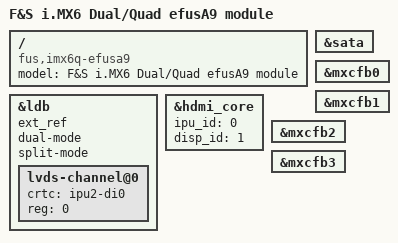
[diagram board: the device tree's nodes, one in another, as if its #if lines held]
/*
 * Copyright (C) 2016 F&S Elektronik Systeme GmbH
 *
 * This program is free software; you can redistribute it and/or modify
 * it under the terms of the GNU General Public License version 2 as
 * published by the Free Software Foundation.
 */

/dts-v1/;

/* Set board revision as 3-digit number, e.g. 110 for board rev. 1.10 */
#define CONFIG_EFUSA9_BOARD_REVISION	120

/* CONFIGURE 5V LVDS POWER SUPPLY */
#if (CONFIG_EFUSA9_BOARD_REVISION >= 121)
/* With REV121 you can connect LVDS displays that need 5V.
   Most displays run with 3.3V. Define the variable below to configure the
   gpio used for switching to 5V. */
//#define CONFIG_EFUSA9_5V_LVDS
#endif


/* ENABLE DISPLAYS */
/* The following display config will be converted to Kconfig in the future */
/* Keep the order, e.G. activating D0 and D3 but not D2 is not allowed */
/* Define this if you have at least one display (D0) */
#define CONFIG_EFUSA9_D0
/* Define this if you have a second display (D1) */
#define CONFIG_EFUSA9_D1
/* Define this if you have a third display (D2) */
//#define CONFIG_EFUSA9_D2
/* Define this if you have a fourth display (D3) */
//#define CONFIG_EFUSA9_D3

/* CONFIGURE DISPLAY 0 */
#ifdef CONFIG_EFUSA9_D0
/* Activate exactly one entry for the type of display D0 */
#define CONFIG_EFUSA9_D0_LCD				// LCD
//#define CONFIG_EFUSA9_D0_LVDS				// LVDS
//#define CONFIG_EFUSA9_D0_HDMI				// HDMI
/*
 * Define a mode_str entry for display D0 (depends on display type above)
 * See the following files for possible values:
 *   LVDS: drivers/video/mxc/ldb.c
 *   LCD:  drivers/video/mxc/mxc_lcdif.c
 *   HDMI: drivers/video/fbdev/mxc/mxc_hdmi.c (actually fetched from panel via EDID)
 */
#ifdef CONFIG_EFUSA9_D0_LCD
	#define CONFIG_EFUSA9_D0_MODE_STR "LCD-ET070080"	// LCD
#elif defined(CONFIG_EFUSA9_D0_LVDS)
	#define CONFIG_EFUSA9_D0_MODE_STR "LDB-WVGA"		// LVDS
#elif defined(CONFIG_EFUSA9_D0_HDMI)
	#define CONFIG_EFUSA9_D0_MODE_STR "1920x1080M@60"	// HDMI
#endif
#endif // CONFIG_EFUSA9_D0

/* CONFIGURE DISPLAY 1 */
#ifdef CONFIG_EFUSA9_D1
/* Activate exactly one entry for the type of display D1 */
//#define CONFIG_EFUSA9_D1_LCD				// LCD
#define CONFIG_EFUSA9_D1_LVDS				// LVDS
//#define CONFIG_EFUSA9_D1_HDMI				// HDMI
/* Define a mode_str entry for display D1 (see comment for D0 above) */
#ifdef CONFIG_EFUSA9_D1_LVDS
	#define CONFIG_EFUSA9_D1_MODE_STR "LDB-WVGA"		// LVDS
#elif defined(CONFIG_EFUSA9_D1_HDMI)
	#define CONFIG_EFUSA9_D1_MODE_STR "1920x1080M@60"	// HDMI
#elif	defined(CONFIG_EFUSA9_D1_LCD)
	#define CONFIG_EFUSA9_D1_MODE_STR "LCD-ET070080"	// LCD
#endif
#endif // CONFIG_EFUSA9_D1

/* CONFIGURE DISPLAY 2 */
#ifdef CONFIG_EFUSA9_D2
/* Activate exactly one entry for the type of display D2 */
//#define CONFIG_EFUSA9_D2_LCD				// LCD
//#define CONFIG_EFUSA9_D2_LVDS				// LVDS
#define CONFIG_EFUSA9_D2_HDMI				// HDMI
/* Define a mode_str entry for display D2 (see comment for D0 above) */
#ifdef CONFIG_EFUSA9_D2_LVDS
	#define CONFIG_EFUSA9_D2_MODE_STR "LDB-WVGA"		// LVDS
#elif defined(CONFIG_EFUSA9_D2_HDMI)
	#define CONFIG_EFUSA9_D2_MODE_STR "1920x1080M@60"	// HDMI
#elif	defined(CONFIG_EFUSA9_D2_LCD)
	#define CONFIG_EFUSA9_D2_MODE_STR "LCD-ET070080"	// LCD
#endif
#endif // CONFIG_EFUSA9_D2

/* CONFIGURE DISPLAY 3 */
#ifdef CONFIG_EFUSA9_D3
/* Activate exactly one entry for the type of display D3 */
//#define CONFIG_EFUSA9_D3_LCD				// LCD
#define CONFIG_EFUSA9_D3_LVDS				// LVDS
//#define CONFIG_EFUSA9_D3_HDMI				// HDMI
/* Define a mode_str entry for display D3 (see comment for D0 above) */
#ifdef CONFIG_EFUSA9_D3_LVDS
	#define CONFIG_EFUSA9_D3_MODE_STR "LDB-WVGA"		// LVDS
#elif defined(CONFIG_EFUSA9_D3_HDMI)
	#define CONFIG_EFUSA9_D3_MODE_STR "1920x1080M@60"	// HDMI
#elif	defined(CONFIG_EFUSA9_D3_LCD)
	#define CONFIG_EFUSA9_D3_MODE_STR "LCD-ET070080"	// LCD
#endif
#endif // CONFIG_EFUSA9_D3

/* CONFIGURE LVDS MULTIDISPLAY*/
/* Two LVDS displays act as two independent displays (with two fb) by default.
   Apart from this  can choose between dual-mode and split-mode */
#if defined(CONFIG_EFUSA9_D0_LVDS) && defined(CONFIG_EFUSA9_D1_LVDS)
/* one LVDS display per channel, one framebuffer for both */
//#define CONFIG_EFUSA9_LVDS_DUAL_MODE
/* two channels for 'split-mode-display', one framebuffer */
//#define CONFIG_EFUSA9_LVDS_SPLIT_MODE
#endif

/* Do some settings to make configurations easier */
#if defined(CONFIG_EFUSA9_D0_LCD) || defined(CONFIG_EFUSA9_D1_LCD) ||\
    defined(CONFIG_EFUSA9_D2_LCD) || defined(CONFIG_EFUSA9_D3_LCD)
#define CONFIG_EFUSA9_LCD // activates LCD node
#endif
#if defined(CONFIG_EFUSA9_D0_HDMI) || defined(CONFIG_EFUSA9_D1_HDMI) ||\
    defined(CONFIG_EFUSA9_D2_HDMI) || defined(CONFIG_EFUSA9_D3_HDMI)
#define CONFIG_EFUSA9_HDMI // activates HDMI node
#endif

#if defined(CONFIG_EFUSA9_D0_LVDS) || defined(CONFIG_EFUSA9_D1_LVDS) ||\
    defined(CONFIG_EFUSA9_D2_LVDS) || defined(CONFIG_EFUSA9_D3_LVDS)
#define CONFIG_EFUSA9_LVDS // activates LVDS node
#endif

/* HDMI */
#ifdef CONFIG_EFUSA9_HDMI
#define CONFIG_EFUSA9_HDMI_AUDIO
#define CONFIG_EFUSA9_HDMI_CEC
#endif


/*
 * Configure touch screen:
 *
 * - 4-wire/5-wire analog resistive touch, touch controller on SKIT
 * - 4-wire/5-wire analog resistive touch, touch controller on RGB LCD adapter
 * - PCAP touch based on Maxtouch controller (MXT224, etc), on Touch Connector
 * - PCAP touch based on Focaltech controller (FT5x06), on Touch Connector
 *
 * On efusA9, all touches use the same interrupt line and I2C bus, so do not
 * select more than one entry! Select none if you do not need touch support.
 */
//#define CONFIG_EFUSA9_4WTOUCH_SX8655_ONBOARD
#define CONFIG_EFUSA9_4WTOUCH_SX8655_RGBADAPTER
//#define CONFIG_EFUSA9_CAPTOUCH_MXT224
//#define CONFIG_EFUSA9_CAPTOUCH_FT5x06

/* CMA: Set 320 MB for Continuous Memory Allocator */
#define CONFIG_EFUSA9_CMA_SIZE		0x14000000

/* NAND */
#define CONFIG_EFUSA9_NAND

/* AUDIO */
#define CONFIG_EFUSA9_SGTL5000_AUDIO

/* Camera connected */
#define CONFIG_EFUSA9_CAMERA

/* Camera on parallel CSI interface */
//#define CONFIG_EFUSA9_PARALLEL_CAMERA

/* Camera on serial MIPI CSI interface */
#define CONFIG_EFUSA9_SERIAL_CAMERA

/* SD-CARD - SD_A is micro SD; SD_B is normalsize SD */
#define CONFIG_EFUSA9_SD_A
#define CONFIG_EFUSA9_SD_B

/* SATA */
#define CONFIG_EFUSA9_SATA

/* EMMC */
//#define CONFIG_EFUSA9_EMMC

/* I2C */
#define CONFIG_EFUSA9_I2C_A
#define CONFIG_EFUSA9_I2C_B
#define CONFIG_EFUSA9_I2C_C

/* SPI */
#define CONFIG_EFUSA9_SPI_A
#define CONFIG_EFUSA9_SPI_B

/* UART */
#define CONFIG_EFUSA9_UART_A
#define CONFIG_EFUSA9_UART_B
#define CONFIG_EFUSA9_UART_C
#define CONFIG_EFUSA9_UART_D


#include "imx6q.dtsi"
#include "efusa9qdl.dtsi"

/ {
	model = "F&S i.MX6 Dual/Quad efusA9 module";
	compatible = "fus,imx6q-efusa9", "fsl,imx6q";
};

/* i.MX6 Dual and Quad can have SATA */
#ifdef CONFIG_EFUSA9_SATA
&sata{
	status = "okay";
};

#endif
#ifdef CONFIG_EFUSA9_LVDS
&ldb {
	ext_ref;
#ifdef CONFIG_EFUSA9_LVDS_DUAL_MODE
	 dual-mode;
#endif
#ifdef CONFIG_EFUSA9_LVDS_SPLIT_MODE
	split-mode;
#endif

#ifdef CONFIG_EFUSA9_D2 		// 3 or 4 displays
#if defined(CONFIG_EFUSA9_LCD) && defined(CONFIG_EFUSA9_HDMI) &&\
    !defined(CONFIG_EFUSA9_D3) 	// 3 displays: LCD, HDMI and LVDS
	lvds-channel@0 {
		crtc = "ipu2-di0";
		reg = <0>;
		status = "okay";
	};
#else	// remaining combinations with 3 or 4 displays
	lvds-channel@0 {
		crtc = "ipu2-di0";
		reg = <0>;
		status = "okay";
	};
	lvds-channel@1 {
		crtc = "ipu2-di1";
		reg = <1>;
		status = "okay";
	};

#endif
#else // 1 or 2 displays

#ifdef CONFIG_EFUSA9_LCD		//if LCD is enabled too, LVDS uses di1
	lvds-channel@0 {
		crtc = "ipu1-di1"; 	//ipu1-di1 means ipu 0, di1
		reg = <0>;
		status = "okay";
	};
#else
	lvds-channel@0 {		//default LVDS uses di0
		crtc = "ipu1-di0";
		reg = <0>;
		status = "okay";
	};
#endif
#ifdef CONFIG_EFUSA9_D1_LVDS		//if both LVDS channels are used
	lvds-channel@1 {		//dual and split mode ignore this node
		crtc = "ipu1-di1";
		reg = <1>;
		status = "okay";
	};
#endif
#endif // 1 or 2 displays
};
#endif

#ifdef CONFIG_EFUSA9_HDMI
&hdmi_core {
	ipu_id = <0>;
	disp_id = <1>;
	status = "okay";
};
#endif
#ifdef CONFIG_EFUSA9_D0
&mxcfb0 {
	status = "okay";
};
#endif
#ifdef CONFIG_EFUSA9_D1
&mxcfb1 {
	status = "okay";
};
#endif
#ifdef CONFIG_EFUSA9_D2
&mxcfb2 {
	status = "okay";
};
#endif
#ifdef CONFIG_EFUSA9_D3
&mxcfb3 {
	status = "okay";
};
#endif
